# LPC54S018M register map
Vendor: nxp.com; File version: 1.0
CPU: CM4 r0p1, little endian, MPU, FPU, VTOR, 3 interrupt priority bits
Registers are 32-bit, read-write, reset 0x0 unless marked. A register's access mark holds for its fields unless they carry their own. Offsets are from the block's base; [hi:lo] are bit positions.

## CAN0 — LPC54S60x/LPC5460x Controller Area Network Flexible Data
Base 0x4009D000
Same registers: CAN1 0x4009E000
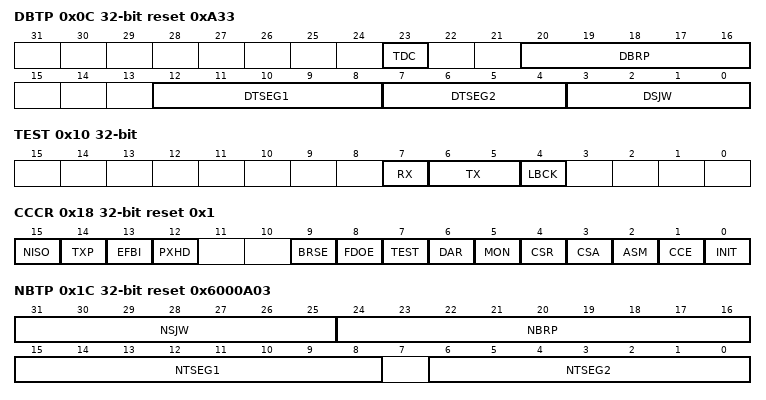
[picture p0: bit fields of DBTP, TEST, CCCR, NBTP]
0x0C DBTP reset 0xA33 — Data Bit Timing Prescaler Register
  [23] TDC — Transmitter delay compensation.
  [20:16] DBRP — Data bit rate prescaler.
  [12:8] DTSEG1 — Data time segment before sample point.
  [7:4] DTSEG2 — Data time segment after sample point.
  [3:0] DSJW — Data (re)synchronization jump width.
0x10 TEST
  [7] RX — Monitors the actual value of the CAN_RXD.
  [6:5] TX — Control of transmit pin.
  [4] LBCK — Loop back mode.
0x18 CCCR reset 0x1 — CC Control Register
  [15] NISO — Non ISO operation.
  [14] TXP — Transmit pause.
  [13] EFBI — Edge filtering during bus integration.
  [12] PXHD — Protocol exception handling disable.
  [9] BRSE — When CAN FD operation is disabled, this bit is not evaluated.
  [8] FDOE — CAN FD operation enable.
  [7] TEST — Test mode enable.
  [6] DAR — Disable automatic retransmission.
  [5] MON — Bus monitoring mode.
  [4] CSR — Clock Stop Request.
  [3] CSA — Clock Stop Acknowledge.
  [2] ASM — Restricted operational mode.
  [1] CCE — Configuration change enable.
  [0] INIT — Initialization.
0x1C NBTP reset 0x6000A03 — Nominal Bit Timing and Prescaler Register
  [31:25] NSJW — Nominal (re)synchronization jump width.
  [24:16] NBRP — Nominal bit rate prescaler.
  [15:8] NTSEG1 — Nominal time segment before sample point.
  [6:0] NTSEG2 — Nominal time segment after sample point.
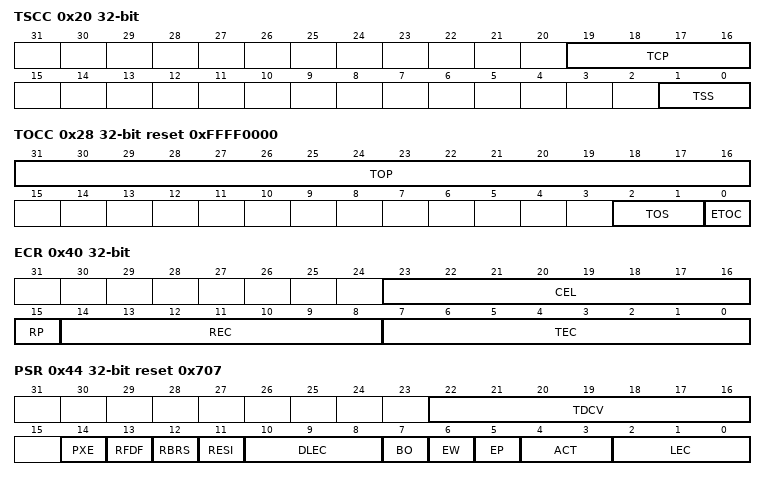
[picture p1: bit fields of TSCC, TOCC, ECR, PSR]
0x20 TSCC — Timestamp Counter Configuration
  [19:16] TCP — Timestamp counter prescaler Configures the timestamp and timeout counters time unit in multiple of CAN bit times.
  [1:0] TSS — Timestamp select.
0x24 TSCV — Timestamp Counter Value
  [15:0] TSC ro — Timestamp counter.
0x28 TOCC reset 0xFFFF0000 — Timeout Counter Configuration
  [31:16] TOP — Timeout period.
  [2:1] TOS — Timeout select.
  [0] ETOC — Enable timeout counter.
0x2C TOCV ro reset 0xFFFF — Timeout Counter Value
  [15:0] TOC — Timeout counter.
0x40 ECR ro — Error Counter Register
  [23:16] CEL — CAN error logging.
  [15] RP — Receive error passive.
  [14:8] REC — Receive error counter.
  [7:0] TEC — Transmit error counter.
0x44 PSR ro reset 0x707 — Protocol Status Register
  [22:16] TDCV — Transmitter delay compensation value.
  [14] PXE — Protocol exception event.
  [13] RFDF — Received a CAN FD message.
  [12] RBRS — BRS flag of last received CAN FD message.
  [11] RESI — ESI flag of the last received CAN FD message.
  [10:8] DLEC — Data phase last error code.
  [7] BO — Bus Off Status.
  [6] EW — Warning status.
  [5] EP — Error Passive.
  [4:3] ACT — Activity.
  [2:0] LEC — Last error code.
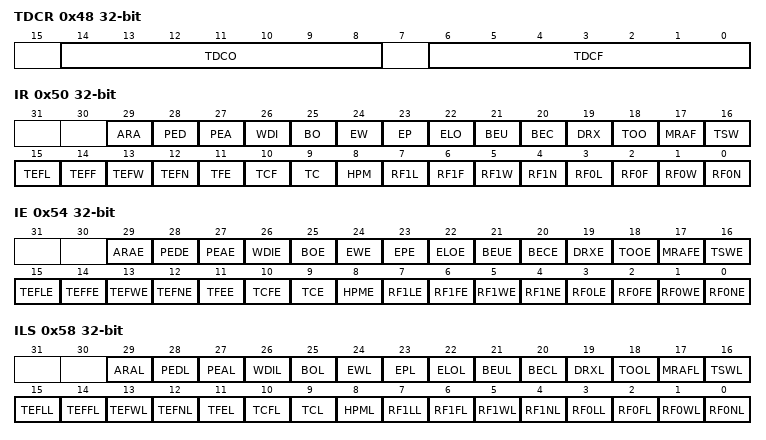
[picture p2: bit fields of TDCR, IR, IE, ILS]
0x48 TDCR — Transmitter Delay Compensator Register
  [14:8] TDCO — Transmitter delay compensation offset.
  [6:0] TDCF — Transmitter delay compensation filter window length.
0x50 IR — Interrupt Register
  [29] ARA — Access to reserved address.
  [28] PED — Protocol error in data phase.
  [27] PEA — Protocol error in arbitration phase.
  [26] WDI — Watchdog interrupt.
  [25] BO — Bus_Off Status.
  [24] EW — Warning status.
  [23] EP — Error passive.
  [22] ELO — Error logging overflow.
  [21] BEU — Bit error uncorrected.
  [20] BEC — Bit error corrected.
  [19] DRX — Message stored in dedicated Rx buffer.
  [18] TOO — Timeout occurred.
  [17] MRAF — Message RAM access failure.
  [16] TSW — Timestamp wraparound.
  [15] TEFL — Tx event FIFO element lost.
  [14] TEFF — Tx event FIFO full.
  [13] TEFW — Tx event FIFO watermark reached.
  [12] TEFN — Tx event FIFO new entry.
  [11] TFE — Tx FIFO empty.
  [10] TCF — Transmission cancellation finished.
  [9] TC — Transmission completed.
  [8] HPM — High priority message.
  [7] RF1L — Rx FIFO 1 message lost.
  [6] RF1F — Rx FIFO 1 full.
  [5] RF1W — Rx FIFO 1 watermark reached.
  [4] RF1N — Rx FIFO 1 new message.
  [3] RF0L — Rx FIFO 0 message lost.
  [2] RF0F — Rx FIFO 0 full.
  [1] RF0W — Rx FIFO 0 watermark reached.
  [0] RF0N — Rx FIFO 0 new message.
0x54 IE — Interrupt Enable
  [29] ARAE — Access to reserved address interrupt enable.
  [28] PEDE — Protocol error in data phase interrupt enable.
  [27] PEAE — Protocol error in arbitration phase interrupt enable.
  [26] WDIE — Watchdog interrupt enable.
  [25] BOE — Bus_Off Status interrupt enable.
  [24] EWE — Warning status interrupt enable.
  [23] EPE — Error passive interrupt enable.
  [22] ELOE — Error logging overflow interrupt enable.
  [21] BEUE — Bit error uncorrected interrupt enable.
  [20] BECE — Bit error corrected interrupt enable.
  [19] DRXE — Message stored in dedicated Rx buffer interrupt enable.
  [18] TOOE — Timeout occurred interrupt enable.
  [17] MRAFE — Message RAM access failure interrupt enable.
  [16] TSWE — Timestamp wraparound interrupt enable.
  [15] TEFLE — Tx event FIFO element lost interrupt enable.
  [14] TEFFE — Tx event FIFO full interrupt enable.
  [13] TEFWE — Tx event FIFO watermark reached interrupt enable.
  [12] TEFNE — Tx event FIFO new entry interrupt enable.
  [11] TFEE — Tx FIFO empty interrupt enable.
  [10] TCFE — Transmission cancellation finished interrupt enable.
  [9] TCE — Transmission completed interrupt enable.
  [8] HPME — High priority message interrupt enable.
  [7] RF1LE — Rx FIFO 1 message lost interrupt enable.
  [6] RF1FE — Rx FIFO 1 full interrupt enable.
  [5] RF1WE — Rx FIFO 1 watermark reached interrupt enable.
  [4] RF1NE — Rx FIFO 1 new message interrupt enable.
  [3] RF0LE — Rx FIFO 0 message lost interrupt enable.
  [2] RF0FE — Rx FIFO 0 full interrupt enable.
  [1] RF0WE — Rx FIFO 0 watermark reached interrupt enable.
  [0] RF0NE — Rx FIFO 0 new message interrupt enable.
0x58 ILS — Interrupt Line Select
  [29] ARAL — Access to reserved address interrupt line.
  [28] PEDL — Protocol error in data phase interrupt line.
  [27] PEAL — Protocol error in arbitration phase interrupt line.
  [26] WDIL — Watchdog interrupt line.
  [25] BOL — Bus_Off Status interrupt line.
  [24] EWL — Warning status interrupt line.
  [23] EPL — Error passive interrupt line.
  [22] ELOL — Error logging overflow interrupt line.
  [21] BEUL — Bit error uncorrected interrupt line.
  [20] BECL — Bit error corrected interrupt line.
  [19] DRXL — Message stored in dedicated Rx buffer interrupt line.
  [18] TOOL — Timeout occurred interrupt line.
  [17] MRAFL — Message RAM access failure interrupt line.
  [16] TSWL — Timestamp wraparound interrupt line.
  [15] TEFLL — Tx event FIFO element lost interrupt line.
  [14] TEFFL — Tx event FIFO full interrupt line.
  [13] TEFWL — Tx event FIFO watermark reached interrupt line.
  [12] TEFNL — Tx event FIFO new entry interrupt line.
  [11] TFEL — Tx FIFO empty interrupt line.
  [10] TCFL — Transmission cancellation finished interrupt line.
  [9] TCL — Transmission completed interrupt line.
  [8] HPML — High priority message interrupt line.
  [7] RF1LL — Rx FIFO 1 message lost interrupt line.
  [6] RF1FL — Rx FIFO 1 full interrupt line.
  [5] RF1WL — Rx FIFO 1 watermark reached interrupt line.
  [4] RF1NL — Rx FIFO 1 new message interrupt line.
  [3] RF0LL — Rx FIFO 0 message lost interrupt line.
  [2] RF0FL — Rx FIFO 0 full interrupt line.
  [1] RF0WL — Rx FIFO 0 watermark reached interrupt line.
  [0] RF0NL — Rx FIFO 0 new message interrupt line.
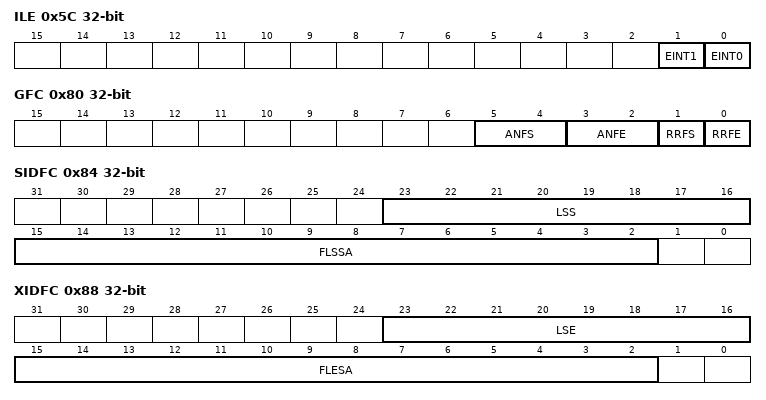
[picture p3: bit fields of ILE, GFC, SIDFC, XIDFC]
0x5C ILE — Interrupt Line Enable
  [1] EINT1 — Enable interrupt line 1.
  [0] EINT0 — Enable interrupt line 0.
0x80 GFC — Global Filter Configuration
  [5:4] ANFS — Accept non-matching frames standard.
  [3:2] ANFE — Accept non-matching frames extended.
  [1] RRFS — Reject remote frames standard.
  [0] RRFE — Reject remote frames extended.
0x84 SIDFC — Standard ID Filter Configuration
  [23:16] LSS — List size standard 0 = No standard message ID filter.
  [15:2] FLSSA — Filter list standard start address.
0x88 XIDFC — Extended ID Filter Configuration
  [23:16] LSE — List size extended 0 = No extended message ID filter.
  [15:2] FLESA — Filter list extended start address.
0x90 XIDAM reset 0x1FFFFFFF — Extended ID AND Mask
  [28:0] EIDM — Extended ID mask.
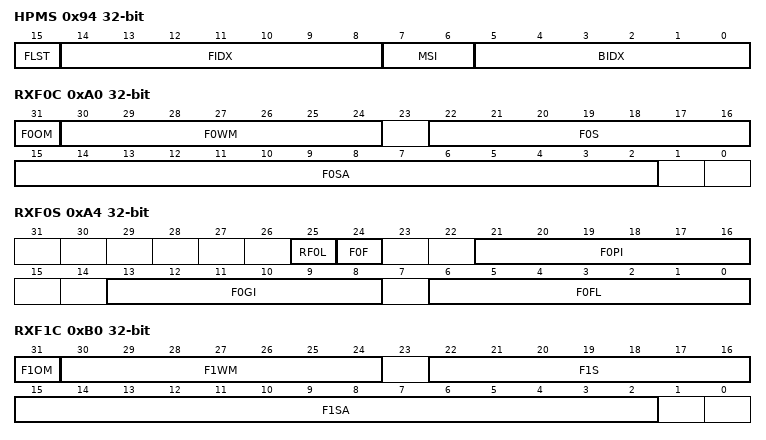
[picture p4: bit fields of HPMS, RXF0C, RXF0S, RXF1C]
0x94 HPMS ro — High Priority Message Status
  [15] FLST — Filter list.
  [14:8] FIDX — Filter index.
  [7:6] MSI — Message storage indicator.
  [5:0] BIDX — Buffer index.
0x98 NDAT1 — New Data 1
  [31:0] ND — New Data.
0x9C NDAT2 — New Data 2
  [31:0] ND — New Data.
0xA0 RXF0C — Rx FIFO 0 Configuration
  [31] F0OM — FIFO 0 operation mode.
  [30:24] F0WM — Rx FIFO 0 watermark 0 = Watermark interrupt disabled.
  [22:16] F0S — Rx FIFO 0 size.
  [15:2] F0SA — Rx FIFO 0 start address.
0xA4 RXF0S — Rx FIFO 0 Status
  [25] RF0L ro — Rx FIFO 0 message lost.
  [24] F0F ro — Rx FIFO 0 full.
  [21:16] F0PI ro — Rx FIFO 0 put index.
  [13:8] F0GI ro — Rx FIFO 0 get index.
  [6:0] F0FL ro — Rx FIFO 0 fill level.
0xA8 RXF0A — Rx FIFO 0 Acknowledge
  [5:0] F0AI — Rx FIFO 0 acknowledge index.
0xAC RXBC — Rx Buffer Configuration
  [15:2] RBSA — Rx buffer start address.
0xB0 RXF1C — Rx FIFO 1 Configuration
  [31] F1OM — FIFO 1 operation mode.
  [30:24] F1WM — Rx FIFO 1 watermark 0 = Watermark interrupt disabled.
  [22:16] F1S — Rx FIFO 1 size 0 = No Rx FIFO 1.
  [15:2] F1SA — Rx FIFO 1 start address.
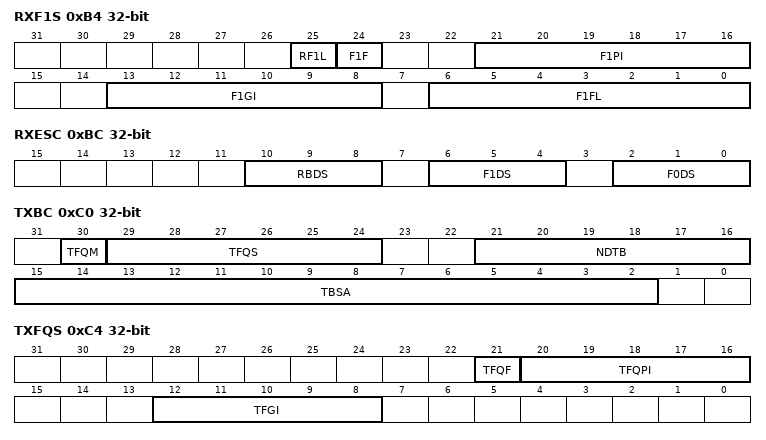
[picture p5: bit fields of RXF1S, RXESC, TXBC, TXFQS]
0xB4 RXF1S ro — Rx FIFO 1 Status
  [25] RF1L — Rx FIFO 1 message lost.
  [24] F1F — Rx FIFO 1 full.
  [21:16] F1PI — Rx FIFO 1 put index.
  [13:8] F1GI — Rx FIFO 1 get index.
  [6:0] F1FL — Rx FIFO 1 fill level.
0xB8 RXF1A — Rx FIFO 1 Acknowledge
  [5:0] F1AI — Rx FIFO 1 acknowledge index.
0xBC RXESC — Rx Buffer and FIFO Element Size Configuration
  [10:8] RBDS
  [6:4] F1DS — Rx FIFO 1 data field size.
  [2:0] F0DS — Rx FIFO 0 data field size.
0xC0 TXBC — Tx Buffer Configuration
  [30] TFQM — Tx FIFO/queue mode.
  [29:24] TFQS — Transmit FIFO/queue size 0 = No tx FIFO/Queue.
  [21:16] NDTB — Number of dedicated transmit buffers 0 = No dedicated Tx buffers.
  [15:2] TBSA — Tx buffers start address.
0xC4 TXFQS — Tx FIFO/Queue Status
  [21] TFQF — Tx FIFO/queue full.
  [20:16] TFQPI — Tx FIFO/queue put index.
  [12:8] TFGI — Tx FIFO get index.
0xC8 TXESC — Tx Buffer Element Size Configuration
  [2:0] TBDS — Tx buffer data field size.
0xCC TXBRP ro — Tx Buffer Request Pending
  [31:0] TRP — Transmission request pending.
0xD0 TXBAR — Tx Buffer Add Request
  [31:0] AR — Add request.
0xD4 TXBCR — Tx Buffer Cancellation Request
  [31:0] CR — Cancellation request.
0xD8 TXBTO ro — Tx Buffer Transmission Occurred
  [31:0] TO — Transmission occurred.
0xDC TXBCF ro — Tx Buffer Cancellation Finished
  [31:0] TO — Cancellation finished.
0xE0 TXBTIE — Tx Buffer Transmission Interrupt Enable
  [31:0] TIE — Transmission interrupt enable.
0xE4 TXBCIE — Tx Buffer Cancellation Finished Interrupt Enable
  [31:0] CFIE — Cancellation finished interrupt enable.
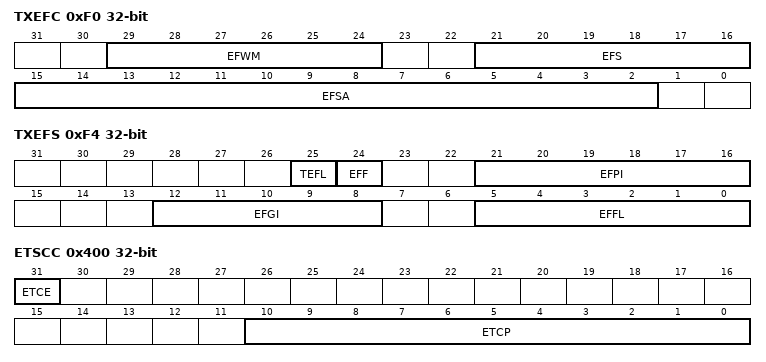
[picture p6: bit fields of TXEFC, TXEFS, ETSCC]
0xF0 TXEFC — Tx Event FIFO Configuration
  [29:24] EFWM — Event FIFO watermark 0 = Watermark interrupt disabled.
  [21:16] EFS — Event FIFO size 0 = Tx event FIFO disabled.
  [15:2] EFSA — Event FIFO start address.
0xF4 TXEFS ro — Tx Event FIFO Status
  [25] TEFL — Tx event FIFO element lost.
  [24] EFF — Event FIFO full.
  [21:16] EFPI — Event FIFO put index.
  [12:8] EFGI — Event FIFO get index.
  [5:0] EFFL — Event FIFO fill level.
0xF8 TXEFA — Tx Event FIFO Acknowledge
  [4:0] EFAI — Event FIFO acknowledge index.
0x200 MRBA — CAN Message RAM Base Address
  [31:16] BA — Base address for the message RAM in the chip memory map.
0x400 ETSCC — External Timestamp Counter Configuration
  [31] ETCE — External timestamp counter enable.
  [10:0] ETCP — External timestamp prescaler value.
0x600 ETSCV — External Timestamp Counter Value
  [15:0] ETSC — External timestamp counter.
